# MKW01Z4 register map
File version: 1.6
Registers are 32-bit, read-write, reset 0x0 unless marked. A register's access mark holds for its fields unless they carry their own. Offsets are from the block's base; [hi:lo] are bit positions; {n}, {i} and the like mark numbered series; 'fields as' and 'values as' point back to an identical list.

## LPTMR0 — Low Power Timer
Base 0x40040000; register names take the prefix LPTMR0_
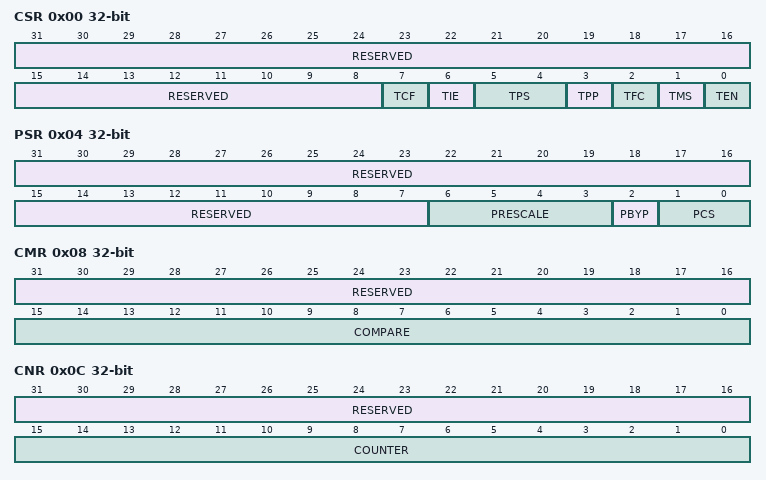
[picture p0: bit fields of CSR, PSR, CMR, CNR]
0x00 CSR — Low Power Timer Control Status Register
  [31:8] RESERVED ro
  [7] TCF — Timer Compare Flag
    0=The value of CNR is not equal to CMR and increments; 1=The value of CNR is equal to CMR and increments
  [6] TIE — Timer Interrupt Enable
    0=Timer interrupt disabled; 1=Timer interrupt enabled
  [5:4] TPS — Timer Pin Select
    {v}=Pulse counter input {v} is selected (v=0..3)
  [3] TPP — Timer Pin Polarity
    0=Pulse Counter input source is active-high, and the CNR will increment on the rising-edge; 1=Pulse Counter input source is active-low, and the CNR will increment on the falling-edge
  [2] TFC — Timer Free-Running Counter
    0=CNR is reset whenever TCF is set; 1=CNR is reset on overflow
  [1] TMS — Timer Mode Select
    0=Time Counter mode; 1=Pulse Counter mode
  [0] TEN — Timer Enable
    0=LPTMR is disabled and internal logic is reset; 1=LPTMR is enabled
0x04 PSR — Low Power Timer Prescale Register
  [31:7] RESERVED ro
  [6:3] PRESCALE — Prescale Value
    0=Prescaler divides the prescaler clock by 2; glitch filter does not support this configuration; 1=Prescaler divides the prescaler clock by 4; glitch filter recognizes change on input pin after 2 rising clock edges; 2=Prescaler divides the prescaler clock by 8; glitch filter recognizes change on input pin after 4 rising clock edges; 3=Prescaler divides the prescaler clock by 16; glitch filter recognizes change on input pin after 8 rising clock edges; 4=Prescaler divides the prescaler clock by 32; glitch filter recognizes change on input pin after 16 rising clock edges; 5=Prescaler divides the prescaler clock by 64; glitch filter recognizes change on input pin after 32 rising clock edges; 6=Prescaler divides the prescaler clock by 128; glitch filter recognizes change on input pin after 64 rising clock edges; 7=Prescaler divides the prescaler clock by 256; glitch filter recognizes change on input pin after 128 rising clock edges; 8=Prescaler divides the prescaler clock by 512; glitch filter recognizes change on input pin after 256 rising clock edges; 9=Prescaler divides the prescaler clock by 1024; glitch filter recognizes change on input pin after 512 rising clock edges; 10=Prescaler divides the prescaler clock by 2048; glitch filter recognizes change on input pin after 1024 rising clock edges; 11=Prescaler divides the prescaler clock by 4096; glitch filter recognizes change on input pin after 2048 rising clock edges; 12=Prescaler divides the prescaler clock by 8192; glitch filter recognizes change on input pin after 4096 rising clock edges; 13=Prescaler divides the prescaler clock by 16,384; glitch filter recognizes change on input pin after 8192 rising clock edges; 14=Prescaler divides the prescaler clock by 32,768; glitch filter recognizes change on input pin after 16,384 rising clock edges; 15=Prescaler divides the prescaler clock by 65,536; glitch filter recognizes change on input pin after 32,768 rising clock edges
  [2] PBYP — Prescaler Bypass
    0=Prescaler/glitch filter is enabled; 1=Prescaler/glitch filter is bypassed
  [1:0] PCS — Prescaler Clock Select
    {v}=Prescaler/glitch filter clock {v} selected (v=0..3)
0x08 CMR — Low Power Timer Compare Register
  [31:16] RESERVED ro
  [15:0] COMPARE — Compare Value
0x0C CNR — Low Power Timer Counter Register
  [31:16] RESERVED ro
  [15:0] COUNTER — Counter Value

## TSI0 — Touch sense input
Base 0x40045000; register names take the prefix TSI0_
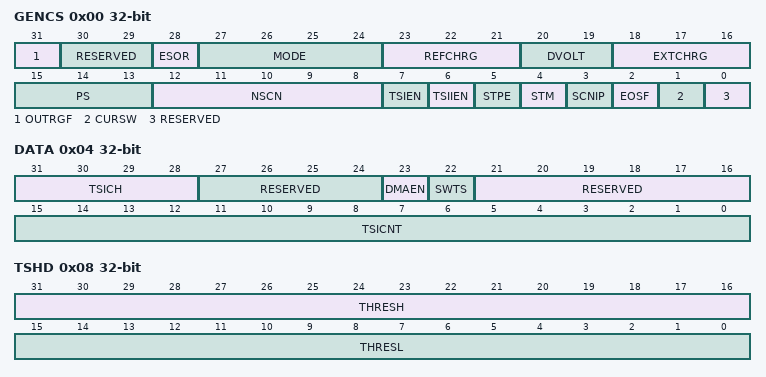
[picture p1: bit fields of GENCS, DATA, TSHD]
0x00 GENCS — TSI General Control and Status Register
  [31] OUTRGF — Out of Range Flag.
  [30:29] RESERVED ro
  [28] ESOR — End-of-scan or Out-of-Range Interrupt Selection
    0=Out-of-range interrupt is allowed; 1=End-of-scan interrupt is allowed
  [27:24] MODE — TSI analog modes setup and status bits.
    0=Set TSI in capacitive sensing(non-noise detection) mode; 4=Set TSI analog to work in single threshold noise detection mode and the frequency limitation circuit is disabled; 8=Set TSI analog to work in single threshold noise detection mode and the frequency limitation circuit is enabled to work in higher frequencies operations; 12=Set TSI analog to work in automatic noise detection mode
  [23:21] REFCHRG
    0=500 nA; 1=1 μA; 2=2 μA; 3=4 μA; 4=8 μA; 5=16 μA; 6=32 μA; 7=64 μA
  [20:19] DVOLT
    0=DV = 1.03 V; VP = 1.33 V; Vm = 0.30 V; 1=DV = 0.73 V; VP = 1.18 V; Vm = 0.45 V; 2=DV = 0.43 V; VP = 1.03 V; Vm = 0.60 V; 3=DV = 0.29 V; VP = 0.95 V; Vm = 0.67 V
  [18:16] EXTCHRG
    values as REFCHRG
  [15:13] PS
    0=Electrode Oscillator Frequency divided by 1; 1=Electrode Oscillator Frequency divided by 2; 2=Electrode Oscillator Frequency divided by 4; 3=Electrode Oscillator Frequency divided by 8; 4=Electrode Oscillator Frequency divided by 16; 5=Electrode Oscillator Frequency divided by 32; 6=Electrode Oscillator Frequency divided by 64; 7=Electrode Oscillator Frequency divided by 128
  [12:8] NSCN
    0=Once per electrode; 1=Twice per electrode; {v}={v+1} times per electrode (v=2..31)
  [7] TSIEN — Touch Sensing Input Module Enable
    0=TSI module disabled; 1=TSI module enabled
  [6] TSIIEN — Touch Sensing Input Interrupt Enable
    0=TSI interrupt is disabled; 1=TSI interrupt is enabled
  [5] STPE — TSI STOP Enable
    0=TSI is disabled when MCU goes into low power mode; 1=Allows TSI to continue running in all low power modes
  [4] STM — Scan Trigger Mode
    0=Software trigger scan; 1=Hardware trigger scan
  [3] SCNIP ro — Scan In Progress Status
    0=No scan in progress; 1=Scan in progress
  [2] EOSF — End of Scan Flag
    0=Scan not complete; 1=Scan complete
  [1] CURSW
    0=The current source pair are not swapped; 1=The current source pair are swapped
  [0] RESERVED ro
0x04 DATA — TSI DATA Register
  [31:28] TSICH
    {v}=Channel {v} (v=0..15)
  [27:24] RESERVED ro
  [23] DMAEN — DMA Transfer Enabled
    0=Interrupt is selected when the interrupt enable bit is set and the corresponding TSI events assert; 1=DMA transfer request is selected when the interrupt enable bit is set and the corresponding TSI events assert
  [22] SWTS wo — Software Trigger Start
    0=No effect; 1=Start a scan to determine which channel is specified by TSI_DATA[TSICH]
  [21:16] RESERVED ro
  [15:0] TSICNT ro — TSI Conversion Counter Value
0x08 TSHD — TSI Threshold Register
  [31:16] THRESH — TSI Wakeup Channel High-threshold
  [15:0] THRESL — TSI Wakeup Channel Low-threshold
